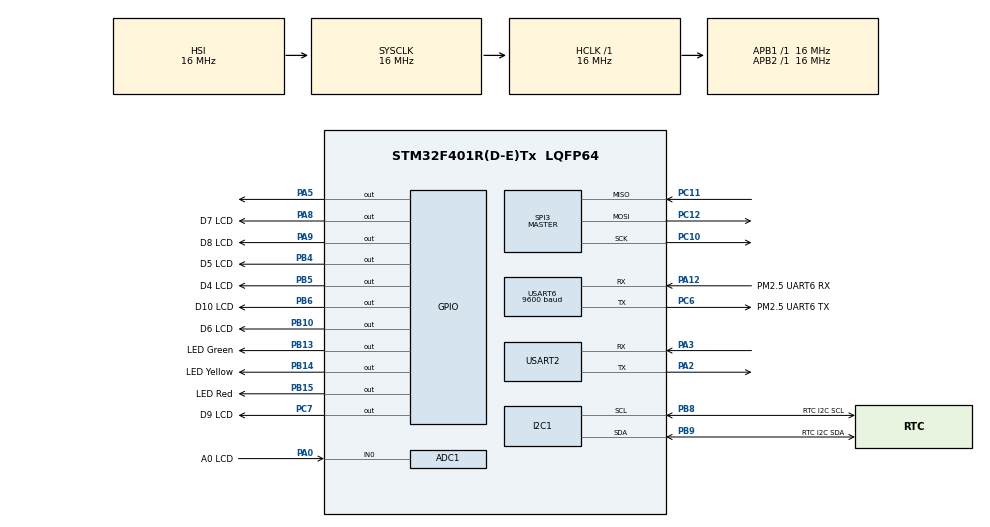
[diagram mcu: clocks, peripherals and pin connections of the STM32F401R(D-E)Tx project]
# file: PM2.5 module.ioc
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ADC1.Channel-0\#ChannelRegularConversion=ADC_CHANNEL_0
ADC1.NbrOfConversionFlag=1
ADC1.Rank-0\#ChannelRegularConversion=1
ADC1.SamplingTime-0\#ChannelRegularConversion=ADC_SAMPLETIME_3CYCLES
ADC1.master=1
Dma.Request0=USART6_RX
Dma.Request1=USART2_TX
Dma.USART2_TX.1.Direction=DMA_MEMORY_TO_PERIPH
Dma.USART2_TX.1.FIFOMode=DMA_FIFOMODE_DISABLE
Dma.USART2_TX.1.Instance=DMA1_Stream6
Dma.USART2_TX.1.MemDataAlignment=DMA_MDATAALIGN_BYTE
Dma.USART2_TX.1.MemInc=DMA_MINC_ENABLE
Dma.USART2_TX.1.Mode=DMA_CIRCULAR
Dma.USART2_TX.1.PeriphDataAlignment=DMA_PDATAALIGN_BYTE
Dma.USART2_TX.1.PeriphInc=DMA_PINC_DISABLE
Dma.USART2_TX.1.Priority=DMA_PRIORITY_LOW
Dma.USART6_RX.0.Direction=DMA_PERIPH_TO_MEMORY
Dma.USART6_RX.0.FIFOMode=DMA_FIFOMODE_DISABLE
Dma.USART6_RX.0.Instance=DMA2_Stream1
Dma.USART6_RX.0.MemDataAlignment=DMA_MDATAALIGN_BYTE
Dma.USART6_RX.0.MemInc=DMA_MINC_ENABLE
Dma.USART6_RX.0.Mode=DMA_CIRCULAR
Dma.USART6_RX.0.PeriphDataAlignment=DMA_PDATAALIGN_BYTE
Dma.USART6_RX.0.PeriphInc=DMA_PINC_DISABLE
Dma.USART6_RX.0.Priority=DMA_PRIORITY_LOW
Mcu.Family=STM32F4
Mcu.Name=STM32F401R(D-E)Tx
Mcu.Package=LQFP64
NVIC.DMA1_Stream6_IRQn=true\:0\:0\:false\:false\:true\:false\:true
NVIC.DMA2_Stream1_IRQn=true\:0\:0\:false\:false\:true\:false\:true
NVIC.PriorityGroup=NVIC_PRIORITYGROUP_4
NVIC.TIM3_IRQn=true\:0\:0\:false\:false\:true\:false\:true
NVIC.TimeBase=TIM3_IRQn
NVIC.TimeBaseIP=TIM3
NVIC.USART2_IRQn=true\:0\:0\:false\:false\:true\:true\:true
NVIC.USART6_IRQn=true\:0\:0\:false\:false\:true\:true\:true
PA0-WKUP.GPIO_Label=A0 LCD
PA0-WKUP.Signal=SharedAnalog_PA0
PA12.GPIO_Label=PM2.5 UART6 RX
PA12.Mode=Asynchronous
PA12.Signal=USART6_RX
PA2.Mode=Asynchronous
PA2.Signal=USART2_TX
PA3.Mode=Asynchronous
PA3.Signal=USART2_RX
PA5.Signal=GPIO_Output
PA8.GPIO_Label=D7 LCD
PA8.Signal=GPIO_Output
PA9.GPIO_Label=D8 LCD
PA9.Signal=GPIO_Output
PB10.GPIO_Label=D6 LCD
PB10.Signal=GPIO_Output
PB13.GPIO_Label=LED Green
PB13.Signal=GPIO_Output
PB14.GPIO_Label=LED Yellow
PB14.Signal=GPIO_Output
PB15.GPIO_Label=LED Red
PB15.Signal=GPIO_Output
PB4.GPIO_Label=D5 LCD
PB4.Signal=GPIO_Output
PB5.GPIO_Label=D4 LCD
PB5.Signal=GPIO_Output
PB6.GPIO_Label=D10 LCD
PB6.Signal=GPIO_Output
PB8.GPIO_Label=RTC I2C SCL 
PB8.Mode=I2C
PB8.Signal=I2C1_SCL
PB9.GPIO_Label=RTC I2C SDA
PB9.Mode=I2C
PB9.Signal=I2C1_SDA
PC10.Mode=Full_Duplex_Master
PC10.Signal=SPI3_SCK
PC11.Mode=Full_Duplex_Master
PC11.Signal=SPI3_MISO
PC12.Mode=Full_Duplex_Master
PC12.Signal=SPI3_MOSI
PC6.GPIO_Label=PM2.5 UART6 TX
PC6.Mode=Asynchronous
PC6.Signal=USART6_TX
PC7.GPIO_Label=D9 LCD
PC7.Signal=GPIO_Output
PH0\ -\ OSC_IN.Mode=HSE-External-Oscillator
PH0\ -\ OSC_IN.Signal=RCC_OSC_IN
PH1\ -\ OSC_OUT.Mode=HSE-External-Oscillator
PH1\ -\ OSC_OUT.Signal=RCC_OSC_OUT
ProjectManager.HeapSize=0x200
ProjectManager.StackSize=0x400
ProjectManager.TargetToolchain=STM32CubeIDE
RCC.AHBFreq_Value=16000000
RCC.APB1Freq_Value=16000000
RCC.APB2Freq_Value=16000000
RCC.CortexFreq_Value=16000000
RCC.HSE_VALUE=25000000
RCC.HSI_VALUE=16000000
RCC.LSE_VALUE=32768
RCC.SYSCLKFreq_VALUE=16000000
RCC.VCOOutputFreq_Value=192000000
SH.SharedAnalog_PA0.0=GPIO_Analog
SH.SharedAnalog_PA0.1=ADC1_IN0,IN0
SPI3.Direction=SPI_DIRECTION_2LINES
SPI3.Mode=SPI_MODE_MASTER
SPI3.VirtualType=VM_MASTER
USART2.VirtualMode=VM_ASYNC
USART6.BaudRate=9600
USART6.VirtualMode=VM_ASYNC
VP_SYS_VS_tim3.Mode=TIM3
board=custom

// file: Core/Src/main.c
/* USER CODE BEGIN Header */
/**
  ******************************************************************************
  * @file           : main.c
  * @brief          : Main program body
  ******************************************************************************
  * @attention
  *
  * <h2><center>&copy; Copyright (c) 2020 STMicroelectronics.
  * All rights reserved.</center></h2>
  *
  * This software component is licensed by ST under BSD 3-Clause license,
  * the "License"; You may not use this file except in compliance with the
  * License. You may obtain a copy of the License at:
  *                        opensource.org/licenses/BSD-3-Clause
  *
  ******************************************************************************
  */
/* USER CODE END Header */

#include "main.h"

/* USER CODE BEGIN Includes */
#include "PMmodule.h"
#include "retarget.h"
#include "lcd.h"
/* USER CODE END Includes */

ADC_HandleTypeDef hadc1;

I2C_HandleTypeDef hi2c1;

SPI_HandleTypeDef hspi3;

UART_HandleTypeDef huart2;
UART_HandleTypeDef huart6;
DMA_HandleTypeDef hdma_usart2_tx;
DMA_HandleTypeDef hdma_usart6_rx;

void SystemClock_Config(void);
static void MX_GPIO_Init(void);
static void MX_ADC1_Init(void);
static void MX_I2C1_Init(void);
static void MX_USART2_UART_Init(void);
static void MX_USART6_UART_Init(void);
static void MX_SPI3_Init(void);
static void MX_DMA_Init(void);

/* USER CODE BEGIN 0 */
uint8_t pmflag[32];
/* USER CODE END 0 */

int main(void)
{

  /* MCU Configuration--------------------------------------------------------*/

  /* Reset of all peripherals, Initializes the Flash interface and the Systick. */
  HAL_Init();

  /* Configure the system clock */
  SystemClock_Config();

  /* Initialize all configured peripherals */
  MX_GPIO_Init();
  MX_ADC1_Init();
  MX_I2C1_Init();
  MX_USART2_UART_Init();
  MX_USART6_UART_Init();
  MX_SPI3_Init();
  MX_DMA_Init();
  /* USER CODE BEGIN 2 */
  RetargetInit(&huart2);
  Lcd_HandleTypeDef lcd;
  Lcd_PortType ports[] = {D4_GPIO_Port, D5_GPIO_Port, D6_GPIO_Port, D7_GPIO_Port};
  Lcd_PinType pins[] = {D4_Pin, D5_Pin, D6_Pin, D7_Pin};
  HAL_GPIO_WritePin(BL_GPIO_Port, BL_Pin, GPIO_PIN_SET);
  lcd = Lcd_create(ports, pins, RS_GPIO_Port, RS_Pin, EN_GPIO_Port, EN_Pin, LCD_4_BIT_MODE);
  Lcd_string(&lcd, "Initialising");
  /* USER CODE END 2 */

  /* Infinite loop */
  while (1)
  {
	uint16_t PM2_5 = 0;
	if(HAL_UART_Receive_IT(&huart6, pmflag, 32)==HAL_OK){
	  //HAL_UART_Transmit_IT(&huart2, pmflag, 31);
	  if (pmflag[0]==0x42){
		  HAL_GPIO_TogglePin(GPIOA,GPIO_PIN_5);
		  if(PMchecksum(pmflag,32)==1){
			  //printf("checksum error\r\n");
		  }
		  PM2_5 = transmitPM2_5(pmflag);
		  printf("The Current PM2.5 is: %d\r\n",PM2_5);
		  Lcd_clear(&lcd);
		  //HAL_Delay(20);
		  //Lcd_cursor(&lcd,1,0);
		  //Lcd_string(&lcd, "PM2.5 Monitoring..");
		  Lcd_cursor(&lcd,0,0);
		  Lcd_string(&lcd, "PM2.5 is:");
		  Lcd_cursor(&lcd,0,10);
		  Lcd_int(&lcd,PM2_5);
	  }
	  else
	  {
		  HAL_Delay(1);
	  }
	  HAL_Delay(1000);

	}
  }
}

void SystemClock_Config(void)
{
  RCC_OscInitTypeDef RCC_OscInitStruct = {0};
  RCC_ClkInitTypeDef RCC_ClkInitStruct = {0};

  /** Configure the main internal regulator output voltage
  */
  __HAL_RCC_PWR_CLK_ENABLE();
  __HAL_PWR_VOLTAGESCALING_CONFIG(PWR_REGULATOR_VOLTAGE_SCALE2);
  /** Initializes the CPU, AHB and APB busses clocks
  */
  RCC_OscInitStruct.OscillatorType = RCC_OSCILLATORTYPE_HSI;
  RCC_OscInitStruct.HSIState = RCC_HSI_ON;
  RCC_OscInitStruct.HSICalibrationValue = RCC_HSICALIBRATION_DEFAULT;
  RCC_OscInitStruct.PLL.PLLState = RCC_PLL_NONE;
  if (HAL_RCC_OscConfig(&RCC_OscInitStruct) != HAL_OK)
  {
    Error_Handler();
  }
  /** Initializes the CPU, AHB and APB busses clocks
  */
  RCC_ClkInitStruct.ClockType = RCC_CLOCKTYPE_HCLK|RCC_CLOCKTYPE_SYSCLK
                              |RCC_CLOCKTYPE_PCLK1|RCC_CLOCKTYPE_PCLK2;
  RCC_ClkInitStruct.SYSCLKSource = RCC_SYSCLKSOURCE_HSI;
  RCC_ClkInitStruct.AHBCLKDivider = RCC_SYSCLK_DIV1;
  RCC_ClkInitStruct.APB1CLKDivider = RCC_HCLK_DIV1;
  RCC_ClkInitStruct.APB2CLKDivider = RCC_HCLK_DIV1;

  if (HAL_RCC_ClockConfig(&RCC_ClkInitStruct, FLASH_LATENCY_0) != HAL_OK)
  {
    Error_Handler();
  }
}

static void MX_ADC1_Init(void)
{

  ADC_ChannelConfTypeDef sConfig = {0};

  /** Configure the global features of the ADC (Clock, Resolution, Data Alignment and number of conversion)
  */
  hadc1.Instance = ADC1;
  hadc1.Init.ClockPrescaler = ADC_CLOCK_SYNC_PCLK_DIV2;
  hadc1.Init.Resolution = ADC_RESOLUTION_12B;
  hadc1.Init.ScanConvMode = DISABLE;
  hadc1.Init.ContinuousConvMode = DISABLE;
  hadc1.Init.DiscontinuousConvMode = DISABLE;
  hadc1.Init.ExternalTrigConvEdge = ADC_EXTERNALTRIGCONVEDGE_NONE;
  hadc1.Init.ExternalTrigConv = ADC_SOFTWARE_START;
  hadc1.Init.DataAlign = ADC_DATAALIGN_RIGHT;
  hadc1.Init.NbrOfConversion = 1;
  hadc1.Init.DMAContinuousRequests = DISABLE;
  hadc1.Init.EOCSelection = ADC_EOC_SINGLE_CONV;
  if (HAL_ADC_Init(&hadc1) != HAL_OK)
  {
    Error_Handler();
  }
  /** Configure for the selected ADC regular channel its corresponding rank in the sequencer and its sample time.
  */
  sConfig.Channel = ADC_CHANNEL_0;
  sConfig.Rank = 1;
  sConfig.SamplingTime = ADC_SAMPLETIME_3CYCLES;
  if (HAL_ADC_ConfigChannel(&hadc1, &sConfig) != HAL_OK)
  {
    Error_Handler();
  }

}

static void MX_I2C1_Init(void)
{

  hi2c1.Instance = I2C1;
  hi2c1.Init.ClockSpeed = 100000;
  hi2c1.Init.DutyCycle = I2C_DUTYCYCLE_2;
  hi2c1.Init.OwnAddress1 = 0;
  hi2c1.Init.AddressingMode = I2C_ADDRESSINGMODE_7BIT;
  hi2c1.Init.DualAddressMode = I2C_DUALADDRESS_DISABLE;
  hi2c1.Init.OwnAddress2 = 0;
  hi2c1.Init.GeneralCallMode = I2C_GENERALCALL_DISABLE;
  hi2c1.Init.NoStretchMode = I2C_NOSTRETCH_DISABLE;
  if (HAL_I2C_Init(&hi2c1) != HAL_OK)
  {
    Error_Handler();
  }

}

static void MX_SPI3_Init(void)
{

  /* SPI3 parameter configuration*/
  hspi3.Instance = SPI3;
  hspi3.Init.Mode = SPI_MODE_MASTER;
  hspi3.Init.Direction = SPI_DIRECTION_2LINES;
  hspi3.Init.DataSize = SPI_DATASIZE_8BIT;
  hspi3.Init.CLKPolarity = SPI_POLARITY_LOW;
  hspi3.Init.CLKPhase = SPI_PHASE_1EDGE;
  hspi3.Init.NSS = SPI_NSS_SOFT;
  hspi3.Init.BaudRatePrescaler = SPI_BAUDRATEPRESCALER_2;
  hspi3.Init.FirstBit = SPI_FIRSTBIT_MSB;
  hspi3.Init.TIMode = SPI_TIMODE_DISABLE;
  hspi3.Init.CRCCalculation = SPI_CRCCALCULATION_DISABLE;
  hspi3.Init.CRCPolynomial = 10;
  if (HAL_SPI_Init(&hspi3) != HAL_OK)
  {
    Error_Handler();
  }

}

static void MX_USART2_UART_Init(void)
{

  huart2.Instance = USART2;
  huart2.Init.BaudRate = 9600;
  huart2.Init.WordLength = UART_WORDLENGTH_8B;
  huart2.Init.StopBits = UART_STOPBITS_1;
  huart2.Init.Parity = UART_PARITY_NONE;
  huart2.Init.Mode = UART_MODE_TX_RX;
  huart2.Init.HwFlowCtl = UART_HWCONTROL_NONE;
  huart2.Init.OverSampling = UART_OVERSAMPLING_16;
  if (HAL_UART_Init(&huart2) != HAL_OK)
  {
    Error_Handler();
  }

}

static void MX_USART6_UART_Init(void)
{

  huart6.Instance = USART6;
  huart6.Init.BaudRate = 9600;
  huart6.Init.WordLength = UART_WORDLENGTH_8B;
  huart6.Init.StopBits = UART_STOPBITS_1;
  huart6.Init.Parity = UART_PARITY_NONE;
  huart6.Init.Mode = UART_MODE_TX_RX;
  huart6.Init.HwFlowCtl = UART_HWCONTROL_NONE;
  huart6.Init.OverSampling = UART_OVERSAMPLING_16;
  if (HAL_UART_Init(&huart6) != HAL_OK)
  {
    Error_Handler();
  }

}

static void MX_DMA_Init(void)
{

  /* DMA controller clock enable */
  __HAL_RCC_DMA2_CLK_ENABLE();
  __HAL_RCC_DMA1_CLK_ENABLE();

  /* DMA interrupt init */
  /* DMA1_Stream6_IRQn interrupt configuration */
  HAL_NVIC_SetPriority(DMA1_Stream6_IRQn, 0, 0);
  HAL_NVIC_EnableIRQ(DMA1_Stream6_IRQn);
  /* DMA2_Stream1_IRQn interrupt configuration */
  HAL_NVIC_SetPriority(DMA2_Stream1_IRQn, 0, 0);
  HAL_NVIC_EnableIRQ(DMA2_Stream1_IRQn);

}

static void MX_GPIO_Init(void)
{
  GPIO_InitTypeDef GPIO_InitStruct = {0};

  /* GPIO Ports Clock Enable */
  __HAL_RCC_GPIOH_CLK_ENABLE();
  __HAL_RCC_GPIOA_CLK_ENABLE();
  __HAL_RCC_GPIOB_CLK_ENABLE();
  __HAL_RCC_GPIOC_CLK_ENABLE();

  /*Configure GPIO pin Output Level */
  HAL_GPIO_WritePin(GPIOA, GPIO_PIN_5|D7_LCD_Pin|D8_LCD_Pin, GPIO_PIN_RESET);

  /*Configure GPIO pin Output Level */
  HAL_GPIO_WritePin(GPIOB, D6_LCD_Pin|LED_Green_Pin|LED_Yellow_Pin|LED_Red_Pin
                          |D5_LCD_Pin|D4_LCD_Pin|D10_LCD_Pin, GPIO_PIN_RESET);

  /*Configure GPIO pin Output Level */
  HAL_GPIO_WritePin(D9_LCD_GPIO_Port, D9_LCD_Pin, GPIO_PIN_RESET);

  /*Configure GPIO pin : A0_LCD_Pin */
  GPIO_InitStruct.Pin = A0_LCD_Pin;
  GPIO_InitStruct.Mode = GPIO_MODE_ANALOG;
  GPIO_InitStruct.Pull = GPIO_NOPULL;
  HAL_GPIO_Init(A0_LCD_GPIO_Port, &GPIO_InitStruct);

  /*Configure GPIO pins : PA5 D7_LCD_Pin D8_LCD_Pin */
  GPIO_InitStruct.Pin = GPIO_PIN_5|D7_LCD_Pin|D8_LCD_Pin;
  GPIO_InitStruct.Mode = GPIO_MODE_OUTPUT_PP;
  GPIO_InitStruct.Pull = GPIO_NOPULL;
  GPIO_InitStruct.Speed = GPIO_SPEED_FREQ_LOW;
  HAL_GPIO_Init(GPIOA, &GPIO_InitStruct);

  /*Configure GPIO pins : D6_LCD_Pin LED_Green_Pin LED_Yellow_Pin LED_Red_Pin
                           D5_LCD_Pin D4_LCD_Pin D10_LCD_Pin */
  GPIO_InitStruct.Pin = D6_LCD_Pin|LED_Green_Pin|LED_Yellow_Pin|LED_Red_Pin
                          |D5_LCD_Pin|D4_LCD_Pin|D10_LCD_Pin;
  GPIO_InitStruct.Mode = GPIO_MODE_OUTPUT_PP;
  GPIO_InitStruct.Pull = GPIO_NOPULL;
  GPIO_InitStruct.Speed = GPIO_SPEED_FREQ_LOW;
  HAL_GPIO_Init(GPIOB, &GPIO_InitStruct);

  /*Configure GPIO pin : D9_LCD_Pin */
  GPIO_InitStruct.Pin = D9_LCD_Pin;
  GPIO_InitStruct.Mode = GPIO_MODE_OUTPUT_PP;
  GPIO_InitStruct.Pull = GPIO_NOPULL;
  GPIO_InitStruct.Speed = GPIO_SPEED_FREQ_LOW;
  HAL_GPIO_Init(D9_LCD_GPIO_Port, &GPIO_InitStruct);

}

void HAL_TIM_PeriodElapsedCallback(TIM_HandleTypeDef *htim)
{
  if (htim->Instance == TIM3) {
    HAL_IncTick();
  }
}

void Error_Handler(void)
{
}

/************************ (C) COPYRIGHT STMicroelectronics *****END OF FILE****/
